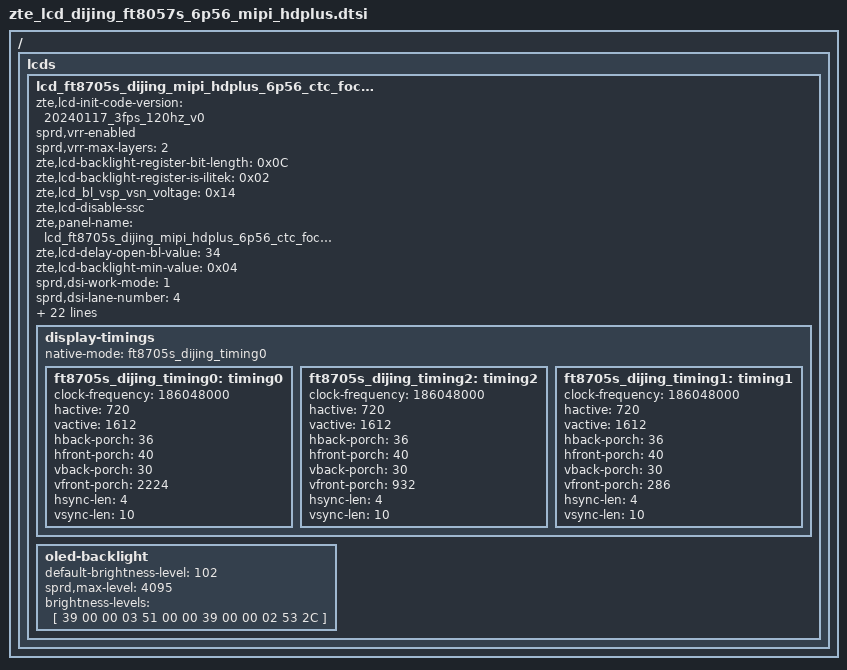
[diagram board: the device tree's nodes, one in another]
/ {
	fragment {
		target-path = "/";
		__overlay__ {
			lcds {
				lcd_ft8705s_dijing_mipi_hdplus_6p56_ctc_focal: lcd_ft8705s_dijing_mipi_hdplus_6p56_ctc_focal {
					zte,lcd-init-code-version = "20240117_3fps_120hz_v0";
					sprd,vrr-enabled;
					sprd,vrr-max-layers = <2>;
					zte,lcd-backlight-register-bit-length = <0x0C>;
					zte,lcd-backlight-register-is-ilitek = <0x02>;/*51h=0xff0f*/
					zte,lcd_bl_vsp_vsn_voltage = <0x14>;
					zte,lcd-disable-ssc;
					zte,panel-name = "lcd_ft8705s_dijing_mipi_hdplus_6p56_ctc_focal";
					zte,lcd-delay-open-bl-value = <34>;
					zte,lcd-backlight-min-value = <0x04>;

					sprd,dsi-work-mode = <1>;
					sprd,dsi-lane-number = <4>;
					sprd,dsi-color-format = "rgb888";

					sprd,dpi-clk-div = <6>;
					sprd,video-lp-cmd-enable = <1>;
					sprd,hporch-lp-disable = <1>;

					sprd,phy-bit-clock = <1116288>;
					sprd,phy-escape-clock = <20000>;/* kHz */

					sprd,width-mm = <67930>;
					sprd,height-mm = <152090>;

					sprd,esd-check-enable = <1>;/* 0:close , 1:open */
					sprd,esd-check-mode = <1>;/* 0:REG ,1:TE  */
					sprd,esd-check-period = <2000>;
					sprd,esd-check-register = <0x0A>;
					sprd,esd-check-value = <0x9C>;

					sprd,dphy-taget-val = <5>;

					sprd,reset-on-sequence = <1 5>, <0 5>, <1 20>;
					sprd,reset-off-sequence = <1 20>;

		sprd,initial-command = [
39 00 00 02 00 00
39 00 00 04 ff 80 57 01
39 00 00 02 00 80
39 00 00 03 ff 80 57
39 00 00 02 00 00
39 00 00 05 2a 00 00 02 cf
39 00 00 02 00 00
39 00 00 05 2b 00 00 06 4b
39 00 00 02 00 a3
39 00 00 05 b3 06 4c 00 18
39 00 00 02 00 93
39 00 00 02 c5 75
39 00 00 02 00 97
39 00 00 02 c5 75
39 00 00 02 00 9a
39 00 00 02 c5 41
39 00 00 02 00 9c
39 00 00 02 c5 41
39 00 00 02 00 b6
39 00 00 03 c5 61 61
39 00 00 02 00 b8
39 00 00 03 c5 37 37
39 00 00 02 00 00
39 00 00 03 d8 33 33
39 00 00 02 00 82
39 00 00 02 c5 55
39 00 00 02 00 83
39 00 00 02 c5 07
39 00 00 02 00 96
39 00 00 02 f5 0d
39 00 00 02 00 86
39 00 00 02 f5 0d
39 00 00 02 00 94
39 00 00 02 c5 15
39 00 00 02 00 9b
39 00 00 02 c5 51
39 00 00 02 00 a3
39 00 00 02 a5 04
39 00 00 02 00 99
39 00 00 02 cf 56
39 00 00 02 00 86
39 00 00 02 b7 80
39 00 00 02 00 a5
39 00 00 02 b0 1d
39 00 00 02 00 ad
39 00 00 04 c1 a0 40 00
39 00 00 02 00 00
39 00 00 11 E1 0D 13 22 31 3A 44 56 62 64 71 72 87 7B 68 68 5D
39 00 00 02 00 10
39 00 00 09 E1 55 49 3A 32 29 1B 10 0F
39 00 00 02 00 00
39 00 00 11 E2 0D 13 22 31 3A 44 56 62 64 71 72 87 7B 68 68 5D
39 00 00 02 00 10
39 00 00 09 E2 55 49 3A 32 29 1B 10 0F
39 00 00 02 00 80
39 00 00 07 c0 00 d2 00 2e 00 1c
39 00 00 02 00 90
39 00 00 07 c0 00 7f 00 2e 00 1c
39 00 00 02 00 a0
39 00 00 07 c0 00 d2 00 2e 00 1c
39 00 00 02 00 b0
39 00 00 06 c0 01 0f 00 2e 1c
39 00 00 02 00 c1
39 00 00 09 c0 01 33 01 0a 00 cd 01 8f
39 00 00 02 00 70
39 00 00 07 c0 00 7f 00 2e 00 1c
39 00 00 02 00 a3
39 00 00 07 c1 00 33 00 3c 00 02
39 00 00 02 00 b7
39 00 00 03 c1 00 33
39 00 00 02 00 73
39 00 00 03 ce 09 09
39 00 00 02 00 80
39 00 00 11 ce 01 81 09 09 00 78 00 96 00 78 00 96 00 78 00 96
39 00 00 02 00 90
39 00 00 10 ce 00 a5 16 8f 00 a5 80 09 09 00 07 d0 16 16 17
39 00 00 02 00 a0
39 00 00 04 ce 20 00 00
39 00 00 02 00 b0
39 00 00 04 ce 87 00 00
39 00 00 02 00 d1
39 00 00 08 ce 00 00 01 00 00 00 00
39 00 00 02 00 e1
39 00 00 0c ce 08 03 c3 03 c3 02 b0 00 00 00 00
39 00 00 02 00 f1
39 00 00 0a ce 14 14 1e 01 52 01 52 01 53
39 00 00 02 00 b0
39 00 00 05 cf 00 00 6d 71
39 00 00 02 00 b5
39 00 00 05 cf 03 03 5b 5f
39 00 00 02 00 c0
39 00 00 05 cf 06 06 47 4b
39 00 00 02 00 c5
39 00 00 05 cf 06 06 4b 4f
39 00 00 02 00 60
39 00 00 09 cf 00 00 6d 71 03 03 5b 5f
39 00 00 02 00 70
39 00 00 09 cf 00 00 65 69 03 03 53 57
39 00 00 02 00 aa
39 00 00 05 cf 80 80 1c 18
39 00 00 02 00 d1
39 00 00 0d c1 03 aa 05 22 09 59 05 87 08 23 0f ac
39 00 00 02 00 e1
39 00 00 03 c1 05 22
39 00 00 02 00 e2
39 00 00 0d cf 06 de 06 dd 06 dd 06 dd 06 dd 06 dd
39 00 00 02 00 80
39 00 00 03 c1 22 22
39 00 00 02 00 90
39 00 00 02 c1 02
39 00 00 02 00 f5
39 00 00 02 cf 00
39 00 00 02 00 f6
39 00 00 02 cf 78
39 00 00 02 00 f1
39 00 00 02 cf 78
39 00 00 02 00 f7
39 00 00 02 cf 11
39 00 00 02 00 00
39 00 00 03 1f 78 78
39 00 00 02 00 d1
39 00 00 08 ce 00 0a 01 01 01 18 01
39 00 00 02 00 e8
39 00 00 05 ce 01 18 01 18
39 00 00 02 00 80
39 00 00 11 cc 26 1c 26 26 26 1d 01 00 00 07 09 0b 0d 0f 11 03
39 00 00 02 00 90
39 00 00 09 cc 05 23 00 00 00 00 00 00
39 00 00 02 00 80
39 00 00 11 cd 26 1c 26 26 26 1d 01 00 00 06 08 0a 0c 0e 10 02
39 00 00 02 00 90
39 00 00 09 cd 04 22 00 00 00 00 00 00
39 00 00 02 00 a0
39 00 00 11 cc 26 26 1c 26 26 1d 01 00 00 08 06 10 0e 0c 0a 04
39 00 00 02 00 b0
39 00 00 09 cc 02 22 00 00 00 00 00 00
39 00 00 02 00 a0
39 00 00 11 cd 26 26 1c 26 26 1d 01 00 00 09 07 11 0f 0d 0b 05
39 00 00 02 00 b0
39 00 00 09 cd 03 23 00 00 00 00 00 00
39 00 00 02 00 80
39 00 00 11 cb c1 c1 c1 c1 c1 c1 c1 c1 c1 c1 c1 c1 c1 c1 c1 c1
39 00 00 02 00 ed
39 00 00 02 cb c1
39 00 00 02 00 90
39 00 00 11 cb 30 00 00 00 00 00 00 00 00 00 00 00 00 00 00 00
39 00 00 02 00 ee
39 00 00 02 cb 00
39 00 00 02 00 90
39 00 00 02 c3 00
39 00 00 02 00 a0
39 00 00 09 cb 00 00 00 00 00 00 00 00
39 00 00 02 00 b0
39 00 00 05 cb 55 55 55 55
39 00 00 02 00 c0
39 00 00 05 cb 55 55 55 55
39 00 00 02 00 d2
39 00 00 0c cb 83 00 83 83 00 83 83 00 83 83 00
39 00 00 02 00 e0
39 00 00 0e cb 83 83 00 83 83 00 83 83 00 83 83 00 83
39 00 00 02 00 fa
39 00 00 03 cb 83 00
39 00 00 02 00 ef
39 00 00 02 cb 00
39 00 00 02 00 68
39 00 00 05 c2 90 05 00 00
39 00 00 02 00 6c
39 00 00 05 c2 8f 05 00 00
39 00 00 02 00 70
39 00 00 05 c2 8e 05 00 00
39 00 00 02 00 74
39 00 00 05 c2 8d 05 00 00
39 00 00 02 00 ea
39 00 00 09 c2 12 00 11 08 00 00 00 00
39 00 00 02 00 8c
39 00 00 06 c2 8a 04 15 4a 9f
39 00 00 02 00 91
39 00 00 06 c2 89 05 15 4a 9f
39 00 00 02 00 96
39 00 00 06 c2 88 06 15 4a 9f
39 00 00 02 00 9b
39 00 00 06 c2 87 07 15 4a 9f
39 00 00 02 00 a0
39 00 00 06 c2 86 00 15 4a 9f
39 00 00 02 00 a5
39 00 00 06 c2 85 00 15 4a 9f
39 00 00 02 00 aa
39 00 00 06 c2 84 00 15 4a 9f
39 00 00 02 00 af
39 00 00 06 c2 83 00 15 4a 9f
39 00 00 02 00 b4
39 00 00 06 c2 82 01 15 4a 9f
39 00 00 02 00 b9
39 00 00 06 c2 81 02 15 4a 9f
39 00 00 02 00 be
39 00 00 06 c2 80 03 15 4a 9f
39 00 00 02 00 c3
39 00 00 06 c2 01 04 15 4a 9f
39 00 00 02 00 dc
39 00 00 09 c2 bb bb bb bb bb bb 00 00
39 00 00 02 00 e8
39 00 00 05 c3 00 00 00 00
39 00 00 02 00 ec
39 00 00 05 c3 00 00 00 00
39 00 00 02 00 f9
39 00 00 02 cb 20
39 00 00 02 00 fe
39 00 00 02 cb 08
39 00 00 02 00 f8
39 00 00 04 cd 8c 55 8b
39 00 00 02 00 fc
39 00 00 03 cb 08 40
39 00 00 02 00 fb
39 00 00 05 c3 93 08 93 08
39 00 00 02 00 98
39 00 00 02 c4 08
39 00 00 02 00 86
39 00 00 04 c3 00 00 00
39 00 00 02 00 90
39 00 00 06 e9 10 ff ff ff 00
39 00 00 02 00 85
39 00 00 02 c4 80
39 00 00 02 00 86
39 00 00 02 a4 b6
39 00 00 02 00 95
39 00 00 02 c4 80
39 00 00 02 00 81
39 00 00 02 a4 73
39 00 00 02 00 ca
39 00 00 03 c0 90 11
39 00 00 02 00 b7
39 00 00 02 f5 1d
39 00 00 02 00 90
39 00 00 02 c3 00
39 00 00 02 00 b1
39 00 00 02 f5 11
39 00 00 02 00 b0
39 00 00 02 c5 00
39 00 00 02 00 b3
39 00 00 02 c5 00
39 00 00 02 00 b2
39 00 00 02 c5 0d
39 00 00 02 00 b5
39 00 00 02 c5 02
39 00 00 02 00 c2
39 00 00 02 f5 42
39 00 00 02 00 80
39 00 00 02 ce 00
39 00 00 02 00 d0
39 00 00 02 ce 01
39 00 00 02 00 e0
39 00 00 02 ce 00
39 00 00 02 00 a1
39 00 00 02 c1 cc
39 00 00 02 00 a5
39 00 00 03 c1 00 1a
39 00 00 02 00 71
39 00 00 06 c0 63 01 2b 00 1e
39 00 00 02 00 B0
39 00 00 04 CA 01 01 0C
39 00 00 02 00 B5
39 00 00 02 CA 04
39 00 00 02 00 00
39 00 00 04 ff 00 00 00
39 00 00 02 00 80
39 00 00 03 ff 00 00
39 00 00 03 51 00 00
39 00 00 02 53 2c
39 00 00 02 55 00
39 00 00 02 35 00
39 78 00 02 11 00
39 0a 00 02 29 00
		];

					sprd,sleep-in-command = [
						05 14 00 01 28
						05 78 00 01 10
						29 00 00 02 00 00
						29 14 00 05 F7 5A A5 95 27
						];
					sprd,sleep-out-command = [
						05 78 00 01 11
						05 64 00 01 29
						];

					display-timings {
						native-mode = <&ft8705s_dijing_timing0>;
						ft8705s_dijing_timing0: timing0 {/*60hz*/
							clock-frequency = <186048000>;
							hactive = <720>;
 							vactive = <1612>;
							hback-porch = <36>;
							hfront-porch = <40>;
 							vback-porch = <30>;
							vfront-porch = <2224>;
							hsync-len = <4>;
 							vsync-len = <10>;
 
 						};
						ft8705s_dijing_timing2: timing2 {/*90hz*/
							clock-frequency = <186048000>;
							hactive = <720>;
							vactive = <1612>;
							hback-porch = <36>;
							hfront-porch = <40>;
							vback-porch = <30>;
							vfront-porch = <932>;
							hsync-len = <4>;
							vsync-len = <10>;
						};

						 ft8705s_dijing_timing1: timing1 {/*120hz*/
							clock-frequency = <186048000>;
 							hactive = <720>;
 							vactive = <1612>;
							hback-porch = <36>;
							hfront-porch = <40>;
							vback-porch = <30>;
							vfront-porch = <286>;
							hsync-len = <4>;
 							vsync-len = <10>;
 
						};
					};
					oled-backlight {
						default-brightness-level = <102>;
						sprd,max-level = <4095>;
						brightness-levels = [
							39 00 00 03 51 00 00
							39 00 00 02 53 2C
						];
					};
				};
			};
		};
	};
};
